# nRF54h20_secure register map
Vendor: Nordic Semiconductor; Series: nRF54h; File version: 1
CPU: CM33 r0p4, little endian, MPU, no FPU, 3 interrupt priority bits, 480 interrupts, 8 SAU regions
Registers are 32-bit, read-write, reset 0x0 unless marked. A register's access mark holds for its fields unless they carry their own. Offsets are from the block's base; [hi:lo] are bit positions; {n}, {i} and the like mark numbered series; 'fields as' and 'values as' point back to an identical list.

## GLOBAL_SECDOMBELLBOARD_NS — BELLBOARD public registers 0
Base 0x4F099000; alternate view of BELLBOARD_NS
Same registers: GLOBAL_SECDOMBELLBOARD_S 0x5F099000 (alternate view of BELLBOARD_S)
{0x0+4i} TASKS_TRIGGER[{i}] (i=0..31) wo — Description collection: Task TRIGGER[n]
  [0] TASKS_TRIGGER — Task TRIGGER[n]
    1=Trigger task

## GLOBAL_VPR120_NS — VPR peripheral registers 0
Base 0x4F8C8000
Same registers: GLOBAL_VPR120_S 0x5F8C8000
{0x0+4i} TASKS_TRIGGER[{i}] (i=0..31) wo — Description collection: VPR task [n] register
  [0] TASKS_TRIGGER — VPR task [n] register
    1=Trigger task

## GLOBAL_MUTEX120_NS — MUTEX 0
Base 0x4F8D2000
Same registers: GLOBAL_MUTEX130_NS 0x4F927000
{0x400+4i} MUTEX[{i}] (i=0..31) — Description collection: Mutex register
  [0] MUTEX — Mutex register n
    0=Unlocked (Mutex n is in unlocked state); 1=Locked (Mutex n is in locked state)

## GLOBAL_CAN120_NS — Controller Area Network 0
Base 0x4F8D8000
Same registers: GLOBAL_CAN120_S 0x5F8D8000
0x00 TASKS_START wo — Start the CAN peripheral.
  [0] TASKS_START
    1=Trigger task
0x04 TASKS_STOPREQ wo — Request to stop the CAN peripheral
  [0] TASKS_STOPREQ
    1=Trigger task
0x08 TASKS_STOP wo — Stop the CAN peripheral
  [0] TASKS_STOP
    1=Trigger task
{0x100+4i} EVENTS_CORE[{i}] (i=0..1) — Description collection: Event indicating that interrupt n triggered at CAN core
  [0] EVENTS_CORE — Event indicating that interrupt n triggered at CAN core
    0=NotGenerated (Event not generated); 1=Generated (Event generated)
0x108 EVENTS_DMU — Event indicating that interrupt triggered at CAN DMU
  [0] EVENTS_DMU
    values as EVENTS_CORE[0].EVENTS_CORE
0x10C EVENTS_DMA — Event indicating that interrupt triggered at CAN DMA
  [0] EVENTS_DMA
    values as EVENTS_CORE[0].EVENTS_CORE
0x110 EVENTS_READYFORSTOP — Event indicating that the CAN is ready to be stopped
  [0] EVENTS_READYFORSTOP
    values as EVENTS_CORE[0].EVENTS_CORE
0x200 SHORTS — Shortcuts between local events and tasks
  [0] READYFORSTOP_STOP — Shortcut between event READYFORSTOP and task STOP
    0=Disabled (Disable shortcut); 1=Enabled (Enable shortcut)
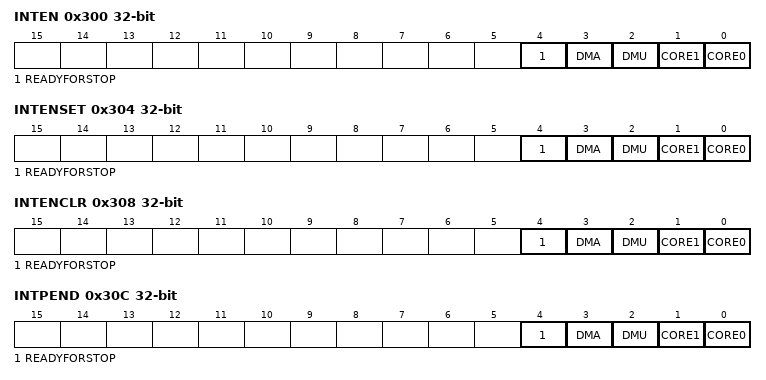
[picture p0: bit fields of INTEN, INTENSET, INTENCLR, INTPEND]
0x300 INTEN — Enable or disable interrupt
  [all] fields
    0=Disabled; 1=Enabled
  [4] READYFORSTOP — Enable or disable interrupt for event READYFORSTOP
  [3] DMA — Enable or disable interrupt for event DMA
  [2] DMU — Enable or disable interrupt for event DMU
  [1] CORE1 — Enable or disable interrupt for event CORE[1]
  [0] CORE0 — Enable or disable interrupt for event CORE[0]
0x304 INTENSET — Enable interrupt
  [all] fields
    on read: 0=Disabled (Read: Disabled); 1=Enabled (Read: Enabled) | on write: 1=Set (Enable)
  [4] READYFORSTOP — Write '1' to enable interrupt for event READYFORSTOP
  [3] DMA — Write '1' to enable interrupt for event DMA
  [2] DMU — Write '1' to enable interrupt for event DMU
  [1] CORE1 — Write '1' to enable interrupt for event CORE[1]
  [0] CORE0 — Write '1' to enable interrupt for event CORE[0]
0x308 INTENCLR — Disable interrupt
  [all] fields
    on read: 0=Disabled (Read: Disabled); 1=Enabled (Read: Enabled) | on write: 1=Clear (Disable)
  [4] READYFORSTOP — Write '1' to disable interrupt for event READYFORSTOP
  [3] DMA — Write '1' to disable interrupt for event DMA
  [2] DMU — Write '1' to disable interrupt for event DMU
  [1] CORE1 — Write '1' to disable interrupt for event CORE[1]
  [0] CORE0 — Write '1' to disable interrupt for event CORE[0]
0x30C INTPEND ro — Pending interrupts
  [all] fields
    on read: 0=NotPending (Read: Not pending); 1=Pending (Read: Pending)
  [4] READYFORSTOP — Read pending status of interrupt for event READYFORSTOP
  [3] DMA — Read pending status of interrupt for event DMA
  [2] DMU — Read pending status of interrupt for event DMU
  [1] CORE1 — Read pending status of interrupt for event CORE[1]
  [0] CORE0 — Read pending status of interrupt for event CORE[0]
